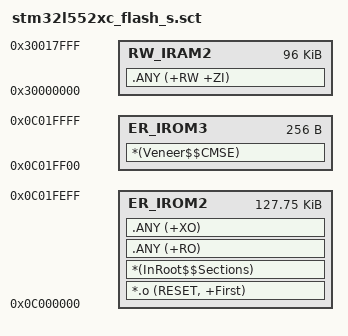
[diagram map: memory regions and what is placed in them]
; *************************************************************
; *** Scatter-Loading Description File generated by uVision ***
; *************************************************************

LR_IROM2 0x0C000000 0x00020000  {    ; load region size_region
  ER_IROM2 0x0C000000 0x0001FF00  {  ; load address = execution address
   *.o (RESET, +First)
   *(InRoot$$Sections)
   .ANY (+RO)
   .ANY (+XO)
  }
  RW_IRAM2 0x30000000 0x00018000  {  ; RW data
   .ANY (+RW +ZI)
  }
}

LR_IROM3 0x0C01FF00 0x00000100  {    ; load region size_region
  ER_IROM3 0x0C01FF00 0x00000100  {  ; load address = execution address
   *(Veneer$$CMSE)                   ; check with partition.h
  }
}
